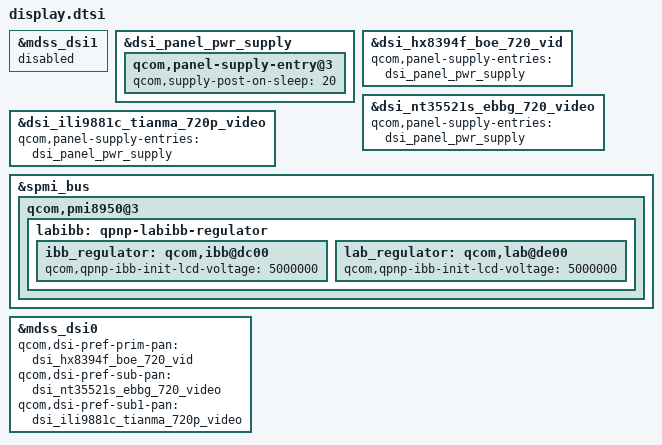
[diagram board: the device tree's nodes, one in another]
#include "panels/dsi-panel-hx8394f-boe-720p-video.dtsi"
#include "panels/dsi-panel-nt35521s-ebbg-720p-video.dtsi"
#include "panels/dsi-panel-ili9881c-tianma-720p-video.dtsi"

/* FROM: wt88537_64.dtsi */
&mdss_dsi1 {
	status = "disabled";
};

&dsi_panel_pwr_supply {
	qcom,panel-supply-entry@3 {
		qcom,supply-post-on-sleep = <20>;
	};
};

&dsi_hx8394f_boe_720_vid {
	qcom,panel-supply-entries = <&dsi_panel_pwr_supply>;
};

&dsi_nt35521s_ebbg_720_video {
	qcom,panel-supply-entries = <&dsi_panel_pwr_supply>;
};

&dsi_ili9881c_tianma_720p_video {
	qcom,panel-supply-entries = <&dsi_panel_pwr_supply>;
};

&spmi_bus {
	qcom,pmi8950@3 {
		labibb: qpnp-labibb-regulator {
			ibb_regulator: qcom,ibb@dc00 {
				qcom,qpnp-ibb-init-lcd-voltage = <5000000>;
			};

			lab_regulator: qcom,lab@de00 {
				qcom,qpnp-ibb-init-lcd-voltage = <5000000>;
			};
		};
	};
};

&mdss_dsi0 {
	qcom,dsi-pref-prim-pan = <&dsi_hx8394f_boe_720_vid>;
	qcom,dsi-pref-sub-pan = <&dsi_nt35521s_ebbg_720_video>;
	qcom,dsi-pref-sub1-pan = <&dsi_ili9881c_tianma_720p_video>;
};
